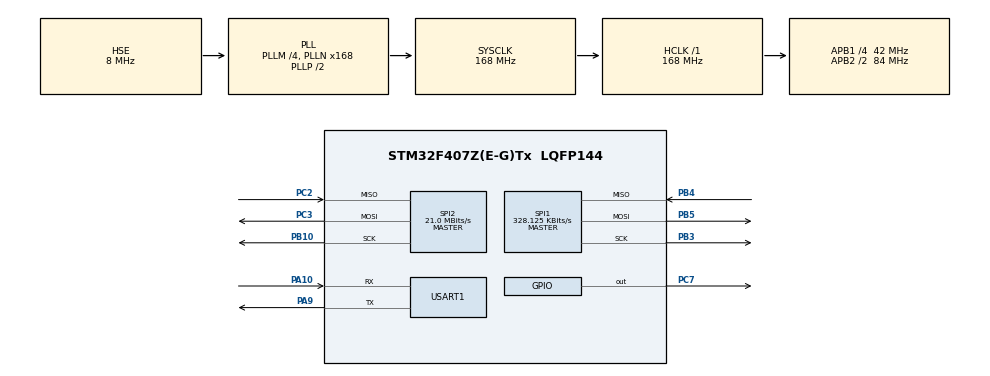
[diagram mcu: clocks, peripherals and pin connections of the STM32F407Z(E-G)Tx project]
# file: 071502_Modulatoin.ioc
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Dma.Request0=SPI1_TX
Dma.Request1=SPI1_RX
Dma.SPI1_RX.1.Direction=DMA_PERIPH_TO_MEMORY
Dma.SPI1_RX.1.FIFOMode=DMA_FIFOMODE_DISABLE
Dma.SPI1_RX.1.Instance=DMA2_Stream2
Dma.SPI1_RX.1.MemDataAlignment=DMA_MDATAALIGN_BYTE
Dma.SPI1_RX.1.MemInc=DMA_MINC_ENABLE
Dma.SPI1_RX.1.Mode=DMA_NORMAL
Dma.SPI1_RX.1.PeriphDataAlignment=DMA_PDATAALIGN_BYTE
Dma.SPI1_RX.1.PeriphInc=DMA_PINC_DISABLE
Dma.SPI1_RX.1.Priority=DMA_PRIORITY_LOW
Dma.SPI1_TX.0.Direction=DMA_MEMORY_TO_PERIPH
Dma.SPI1_TX.0.FIFOMode=DMA_FIFOMODE_DISABLE
Dma.SPI1_TX.0.Instance=DMA2_Stream5
Dma.SPI1_TX.0.MemDataAlignment=DMA_MDATAALIGN_BYTE
Dma.SPI1_TX.0.MemInc=DMA_MINC_ENABLE
Dma.SPI1_TX.0.Mode=DMA_NORMAL
Dma.SPI1_TX.0.PeriphDataAlignment=DMA_PDATAALIGN_BYTE
Dma.SPI1_TX.0.PeriphInc=DMA_PINC_DISABLE
Dma.SPI1_TX.0.Priority=DMA_PRIORITY_LOW
Mcu.Family=STM32F4
Mcu.Name=STM32F407Z(E-G)Tx
Mcu.Package=LQFP144
NVIC.DMA2_Stream2_IRQn=true\:0\:0\:false\:false\:true\:false\:true\:true
NVIC.DMA2_Stream5_IRQn=true\:0\:0\:false\:false\:true\:false\:true\:true
NVIC.PriorityGroup=NVIC_PRIORITYGROUP_4
NVIC.SPI1_IRQn=true\:0\:0\:false\:false\:true\:true\:true\:true
PA10.Mode=Asynchronous
PA10.Signal=USART1_RX
PA13.Mode=Serial_Wire
PA13.Signal=SYS_JTMS-SWDIO
PA14.Mode=Serial_Wire
PA14.Signal=SYS_JTCK-SWCLK
PA9.Mode=Asynchronous
PA9.Signal=USART1_TX
PB10.Mode=Full_Duplex_Master
PB10.Signal=SPI2_SCK
PB3.Mode=Full_Duplex_Master
PB3.Signal=SPI1_SCK
PB4.Mode=Full_Duplex_Master
PB4.Signal=SPI1_MISO
PB5.Mode=Full_Duplex_Master
PB5.Signal=SPI1_MOSI
PC14-OSC32_IN.Mode=LSE-External-Clock-Source
PC14-OSC32_IN.Signal=RCC_OSC32_IN
PC15-OSC32_OUT.Mode=LSE-External-Clock-Source
PC15-OSC32_OUT.Signal=RCC_OSC32_OUT
PC2.Mode=Full_Duplex_Master
PC2.Signal=SPI2_MISO
PC3.Mode=Full_Duplex_Master
PC3.Signal=SPI2_MOSI
PC7.GPIO_Speed=GPIO_SPEED_FREQ_HIGH
PC7.PinState=GPIO_PIN_SET
PC7.Signal=GPIO_Output
PH0-OSC_IN.Mode=HSE-External-Oscillator
PH0-OSC_IN.Signal=RCC_OSC_IN
PH1-OSC_OUT.Mode=HSE-External-Oscillator
PH1-OSC_OUT.Signal=RCC_OSC_OUT
ProjectManager.HeapSize=0x200
ProjectManager.StackSize=0x400
ProjectManager.TargetToolchain=CMake
RCC.48MHZClocksFreq_Value=84000000
RCC.AHBFreq_Value=168000000
RCC.APB1CLKDivider=RCC_HCLK_DIV4
RCC.APB1Freq_Value=42000000
RCC.APB1TimFreq_Value=84000000
RCC.APB2CLKDivider=RCC_HCLK_DIV2
RCC.APB2Freq_Value=84000000
RCC.APB2TimFreq_Value=168000000
RCC.CortexFreq_Value=168000000
RCC.EnbaleCSS=true
RCC.HCLKFreq_Value=168000000
RCC.HSE_VALUE=8000000
RCC.HSI_VALUE=16000000
RCC.LSE_VALUE=32768
RCC.PLLM=4
RCC.PLLN=168
RCC.PLLSourceVirtual=RCC_PLLSOURCE_HSE
RCC.SYSCLKFreq_VALUE=168000000
RCC.SYSCLKSource=RCC_SYSCLKSOURCE_PLLCLK
RCC.VCOOutputFreq_Value=336000000
SPI1.BaudRatePrescaler=SPI_BAUDRATEPRESCALER_256
SPI1.CLKPhase=SPI_PHASE_1EDGE
SPI1.CLKPolarity=SPI_POLARITY_HIGH
SPI1.CalculateBaudRate=328.125 KBits/s
SPI1.Direction=SPI_DIRECTION_2LINES
SPI1.Mode=SPI_MODE_MASTER
SPI1.VirtualType=VM_MASTER
SPI2.CalculateBaudRate=21.0 MBits/s
SPI2.Direction=SPI_DIRECTION_2LINES
SPI2.Mode=SPI_MODE_MASTER
SPI2.VirtualType=VM_MASTER
USART1.VirtualMode=VM_ASYNC
board=custom

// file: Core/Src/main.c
/* USER CODE BEGIN Header */
/**
  ******************************************************************************
  * @file           : main.c
  * @brief          : Main program body
  ******************************************************************************
  * @attention
  *
  * Copyright (c) 2024 STMicroelectronics.
  * All rights reserved.
  *
  * This software is licensed under terms that can be found in the LICENSE file
  * in the root directory of this software component.
  * If no LICENSE file comes with this software, it is provided AS-IS.
  *
  ******************************************************************************
  */
/* USER CODE END Header */
#include "main.h"

SPI_HandleTypeDef hspi1;
SPI_HandleTypeDef hspi2;
DMA_HandleTypeDef hdma_spi1_tx;
DMA_HandleTypeDef hdma_spi1_rx;

UART_HandleTypeDef huart1;
PM004MNIA_Info_Struct pm004mnia_obj;

void SystemClock_Config(void);
static void MX_GPIO_Init(void);
static void MX_DMA_Init(void);
static void MX_USART1_UART_Init(void);
static void MX_SPI1_Init(void);
static void MX_SPI2_Init(void);

/* USER CODE BEGIN 0 */
void HAL_SPI_TxCpltCallback(SPI_HandleTypeDef *hspi) {
    PM004MNIA_Transmit_IRQ_Handler(&pm004mnia_obj, hspi);
}

/* USER CODE END 0 */

int main(void)
{

  /* MCU Configuration--------------------------------------------------------*/

  /* Reset of all peripherals, Initializes the Flash interface and the Systick. */
  HAL_Init();

  /* Configure the system clock */
  SystemClock_Config();

  /* Initialize all configured peripherals */
  MX_GPIO_Init();
  MX_DMA_Init();
  MX_USART1_UART_Init();
  MX_SPI1_Init();
  MX_SPI2_Init();
  /* USER CODE BEGIN 2 */

    //------------------------------AD9833历程------------------------------
    // AD9833_Init(&hspi1);
    // AD9833_SetFrequency(AD9833_REG_FREQ0, 5000.0);
    // AD9833_SetPhase(AD9833_REG_PHASE0, 0);
    // AD9833_SetWave(AD9833_OUT_SINUS, AD9833_FSEL0, AD9833_PSEL0);

    //------------------------------w25qxx历程------------------------------
    // W25QXX_Init(&hspi1);
    // uint8_t buf[] = "homo ahhhh !!!!!";
    // W25QXX_Write(buf, 0x1145, sizeof(buf));
    // uint8_t rx_buf[sizeof(buf)];
    // W25QXX_Read(rx_buf, 0x1145, sizeof(rx_buf));

    // W25QXX_Read(rx_buf, 0x1145, sizeof(rx_buf));
    // HAL_UART_Transmit(&huart1, rx_buf, sizeof(rx_buf), 0x00FF);
    // HAL_Delay(200);

    //------------------------------RFMD2081历程------------------------------
    // RFMD2081_Init();

    //------------------------------PM004MNIA历程------------------------------
    PM004MNIA_Init(&pm004mnia_obj, &hspi1, GPIO_PIN_6, GPIOC, UTILS_DMA);

    //------------------------------测试代码------------------------------

    // uint16_t data = 0;
  /* USER CODE END 2 */
  /* Infinite loop */
  while (1)
  {

    /* USER CODE BEGIN 3 */
    // RFMD2081_Write(RFMD2081_REG_LF, RFMD2081_REG_DEF_VAL_LF);
    // RFMD2081_Write(RFMD2081_REG_LF, RFMD2081_REG_DEF_VAL_LF);
    // data = RFMD2081_Read(RFMD2081_REG_XO);
    // GPIO_PinState state = HAL_GPIO_ReadPin(GPIOF, GPIO_PIN_12);
    // int16_t data = UTILS_Log2(17);
    // printf("%d\n", data);
    // PM004MNIA_Reset(&pm004mnia_obj);
    HAL_Delay(10);
  }
  /* USER CODE END 3 */
}

void SystemClock_Config(void)
{
  RCC_OscInitTypeDef RCC_OscInitStruct = {0};
  RCC_ClkInitTypeDef RCC_ClkInitStruct = {0};

  /** Configure the main internal regulator output voltage
  */
  __HAL_RCC_PWR_CLK_ENABLE();
  __HAL_PWR_VOLTAGESCALING_CONFIG(PWR_REGULATOR_VOLTAGE_SCALE1);

  /** Initializes the RCC Oscillators according to the specified parameters
  * in the RCC_OscInitTypeDef structure.
  */
  RCC_OscInitStruct.OscillatorType = RCC_OSCILLATORTYPE_HSE;
  RCC_OscInitStruct.HSEState = RCC_HSE_ON;
  RCC_OscInitStruct.PLL.PLLState = RCC_PLL_ON;
  RCC_OscInitStruct.PLL.PLLSource = RCC_PLLSOURCE_HSE;
  RCC_OscInitStruct.PLL.PLLM = 4;
  RCC_OscInitStruct.PLL.PLLN = 168;
  RCC_OscInitStruct.PLL.PLLP = RCC_PLLP_DIV2;
  RCC_OscInitStruct.PLL.PLLQ = 4;
  if (HAL_RCC_OscConfig(&RCC_OscInitStruct) != HAL_OK)
  {
    Error_Handler();
  }

  /** Initializes the CPU, AHB and APB buses clocks
  */
  RCC_ClkInitStruct.ClockType = RCC_CLOCKTYPE_HCLK|RCC_CLOCKTYPE_SYSCLK
                              |RCC_CLOCKTYPE_PCLK1|RCC_CLOCKTYPE_PCLK2;
  RCC_ClkInitStruct.SYSCLKSource = RCC_SYSCLKSOURCE_PLLCLK;
  RCC_ClkInitStruct.AHBCLKDivider = RCC_SYSCLK_DIV1;
  RCC_ClkInitStruct.APB1CLKDivider = RCC_HCLK_DIV4;
  RCC_ClkInitStruct.APB2CLKDivider = RCC_HCLK_DIV2;

  if (HAL_RCC_ClockConfig(&RCC_ClkInitStruct, FLASH_LATENCY_5) != HAL_OK)
  {
    Error_Handler();
  }

  /** Enables the Clock Security System
  */
  HAL_RCC_EnableCSS();
}

static void MX_SPI1_Init(void)
{

  /* SPI1 parameter configuration*/
  hspi1.Instance = SPI1;
  hspi1.Init.Mode = SPI_MODE_MASTER;
  hspi1.Init.Direction = SPI_DIRECTION_2LINES;
  hspi1.Init.DataSize = SPI_DATASIZE_8BIT;
  hspi1.Init.CLKPolarity = SPI_POLARITY_HIGH;
  hspi1.Init.CLKPhase = SPI_PHASE_1EDGE;
  hspi1.Init.NSS = SPI_NSS_SOFT;
  hspi1.Init.BaudRatePrescaler = SPI_BAUDRATEPRESCALER_256;
  hspi1.Init.FirstBit = SPI_FIRSTBIT_MSB;
  hspi1.Init.TIMode = SPI_TIMODE_DISABLE;
  hspi1.Init.CRCCalculation = SPI_CRCCALCULATION_DISABLE;
  hspi1.Init.CRCPolynomial = 10;
  if (HAL_SPI_Init(&hspi1) != HAL_OK)
  {
    Error_Handler();
  }

}

static void MX_SPI2_Init(void)
{

  /* SPI2 parameter configuration*/
  hspi2.Instance = SPI2;
  hspi2.Init.Mode = SPI_MODE_MASTER;
  hspi2.Init.Direction = SPI_DIRECTION_2LINES;
  hspi2.Init.DataSize = SPI_DATASIZE_8BIT;
  hspi2.Init.CLKPolarity = SPI_POLARITY_LOW;
  hspi2.Init.CLKPhase = SPI_PHASE_1EDGE;
  hspi2.Init.NSS = SPI_NSS_SOFT;
  hspi2.Init.BaudRatePrescaler = SPI_BAUDRATEPRESCALER_2;
  hspi2.Init.FirstBit = SPI_FIRSTBIT_MSB;
  hspi2.Init.TIMode = SPI_TIMODE_DISABLE;
  hspi2.Init.CRCCalculation = SPI_CRCCALCULATION_DISABLE;
  hspi2.Init.CRCPolynomial = 10;
  if (HAL_SPI_Init(&hspi2) != HAL_OK)
  {
    Error_Handler();
  }

}

static void MX_USART1_UART_Init(void)
{

  huart1.Instance = USART1;
  huart1.Init.BaudRate = 115200;
  huart1.Init.WordLength = UART_WORDLENGTH_8B;
  huart1.Init.StopBits = UART_STOPBITS_1;
  huart1.Init.Parity = UART_PARITY_NONE;
  huart1.Init.Mode = UART_MODE_TX_RX;
  huart1.Init.HwFlowCtl = UART_HWCONTROL_NONE;
  huart1.Init.OverSampling = UART_OVERSAMPLING_16;
  if (HAL_UART_Init(&huart1) != HAL_OK)
  {
    Error_Handler();
  }

}

static void MX_DMA_Init(void)
{

  /* DMA controller clock enable */
  __HAL_RCC_DMA2_CLK_ENABLE();

  /* DMA interrupt init */
  /* DMA2_Stream2_IRQn interrupt configuration */
  HAL_NVIC_SetPriority(DMA2_Stream2_IRQn, 0, 0);
  HAL_NVIC_EnableIRQ(DMA2_Stream2_IRQn);
  /* DMA2_Stream5_IRQn interrupt configuration */
  HAL_NVIC_SetPriority(DMA2_Stream5_IRQn, 0, 0);
  HAL_NVIC_EnableIRQ(DMA2_Stream5_IRQn);

}

static void MX_GPIO_Init(void)
{
  GPIO_InitTypeDef GPIO_InitStruct = {0};

  /* GPIO Ports Clock Enable */
  __HAL_RCC_GPIOC_CLK_ENABLE();
  __HAL_RCC_GPIOH_CLK_ENABLE();
  __HAL_RCC_GPIOB_CLK_ENABLE();
  __HAL_RCC_GPIOA_CLK_ENABLE();

  /*Configure GPIO pin Output Level */
  HAL_GPIO_WritePin(GPIOC, GPIO_PIN_7, GPIO_PIN_SET);

  /*Configure GPIO pin : PC7 */
  GPIO_InitStruct.Pin = GPIO_PIN_7;
  GPIO_InitStruct.Mode = GPIO_MODE_OUTPUT_PP;
  GPIO_InitStruct.Pull = GPIO_NOPULL;
  GPIO_InitStruct.Speed = GPIO_SPEED_FREQ_HIGH;
  HAL_GPIO_Init(GPIOC, &GPIO_InitStruct);

}

void Error_Handler(void)
{
  __disable_irq();
  while (1)
  {
  }
}
